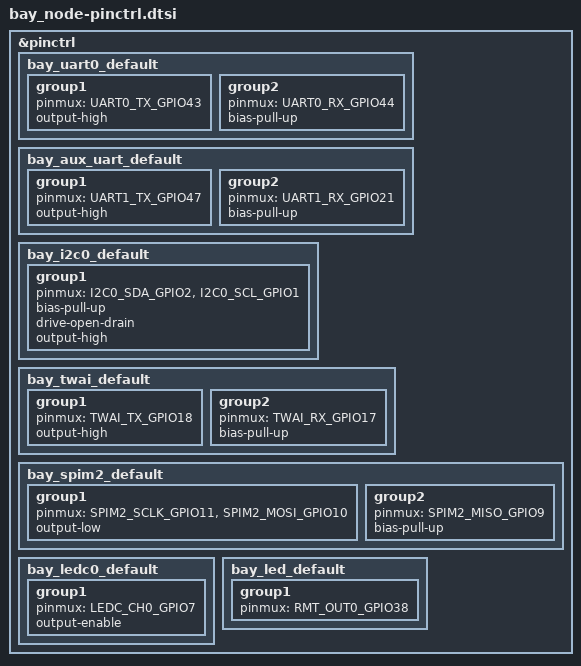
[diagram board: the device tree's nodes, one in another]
/*
 * Bay node pin multiplexing (ESP32-S3-WROOM-1-N8R8).
 *
 * Source of truth: electronics/bay-node/design.py (U3 pin map).
 *
 * SPDX-License-Identifier: Apache-2.0
 */

#include <zephyr/dt-bindings/pinctrl/esp32s3-pinctrl.h>

&pinctrl {
	/* TXD0/RXD0: UART test pads TP1/TP2 (node console) */
	bay_uart0_default: bay_uart0_default {
		group1 {
			pinmux = <UART0_TX_GPIO43>;
			output-high;
		};

		group2 {
			pinmux = <UART0_RX_GPIO44>;
			bias-pull-up;
		};
	};

	/* IO47 AUX_TX / IO21 AUX_RX: DUT console on the AUX connector (1k series) */
	bay_aux_uart_default: bay_aux_uart_default {
		group1 {
			pinmux = <UART1_TX_GPIO47>;
			output-high;
		};

		group2 {
			pinmux = <UART1_RX_GPIO21>;
			bias-pull-up;
		};
	};

	/* IO2 I2C_SDA / IO1 I2C_SCL: INA226 (4.7k pull-ups on the board) */
	bay_i2c0_default: bay_i2c0_default {
		group1 {
			pinmux = <I2C0_SDA_GPIO2>,
				 <I2C0_SCL_GPIO1>;
			bias-pull-up;
			drive-open-drain;
			output-high;
		};
	};

	/* IO18 CAN_TXD / IO17 CAN_RXD: TCAN1462V U11 on the rack bus (docs/can.md) */
	bay_twai_default: bay_twai_default {
		group1 {
			pinmux = <TWAI_TX_GPIO18>;
			output-high;
		};

		group2 {
			pinmux = <TWAI_RX_GPIO17>;
			bias-pull-up;
		};
	};

	/*
	 * J6, the bay camera (Arducam Mega, SPI2 through the GPIO matrix, 33R
	 * series): IO11 CAM_SCK, IO10 CAM_MOSI, IO9 CAM_MISO; CAM_CS on IO8
	 * (cs-gpios, 10k pull-up)
	 */
	bay_spim2_default: bay_spim2_default {
		group1 {
			pinmux = <SPIM2_SCLK_GPIO11>,
				 <SPIM2_MOSI_GPIO10>;
			output-low;
		};

		group2 {
			pinmux = <SPIM2_MISO_GPIO9>;
			bias-pull-up;
		};
	};

	/* IO7 CAM_LED: AO3400A on LED_K, 100k gate pull-down (off at boot) */
	bay_ledc0_default: bay_ledc0_default {
		group1 {
			pinmux = <LEDC_CH0_GPIO7>;
			output-enable;
		};
	};

	/* IO38 LED_DIN: WS2812B status LED (33R series), the DevKitC-1 v1.1's RGB LED pin */
	bay_led_default: bay_led_default {
		group1 {
			pinmux = <RMT_OUT0_GPIO38>;
		};
	};
};
